# STM32F334R8T7 register map
File version: 1.0
Registers are 32-bit, access not given, reset 0x0 unless marked. A register's access mark holds for its fields unless they carry their own. Offsets are from the block's base; [hi:lo] are bit positions; {n}, {i} and the like mark numbered series.

## HRTIM1_COMMON
Base 0x40017780
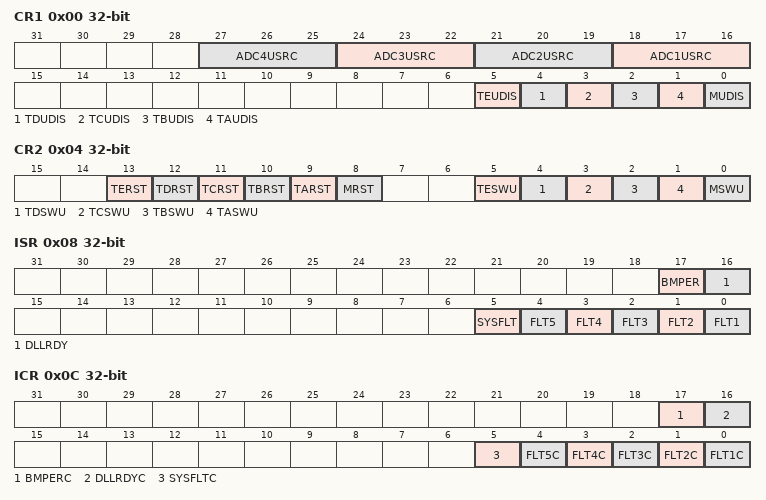
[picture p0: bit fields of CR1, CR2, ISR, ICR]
0x00 CR1
  [3n+15:3n+13] ADC{n}USRC (n=1..4), [5] TEUDIS, [4] TDUDIS, [3] TCUDIS, [2] TBUDIS, [1] TAUDIS, [0] MUDIS
0x04 CR2
  [13] TERST, [12] TDRST, [11] TCRST, [10] TBRST, [9] TARST, [8] MRST, [5] TESWU, [4] TDSWU, [3] TCSWU, [2] TBSWU, [1] TASWU, [0] MSWU
0x08 ISR
  [17] BMPER, [16] DLLRDY, [5] SYSFLT, [n-1] FLT{n} (n=1..5)
0x0C ICR
  [17] BMPERC, [16] DLLRDYC, [5] SYSFLTC, [n-1] FLT{n}C (n=1..5)
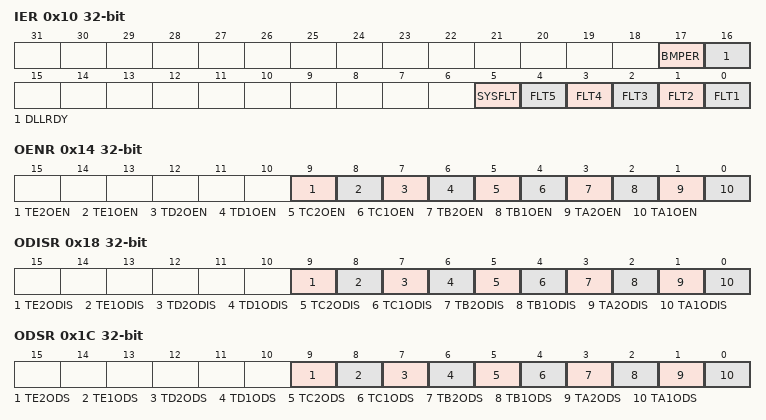
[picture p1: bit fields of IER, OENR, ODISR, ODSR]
0x10 IER
  [17] BMPER, [16] DLLRDY, [5] SYSFLT, [n-1] FLT{n} (n=1..5)
0x14 OENR
  [9] TE2OEN, [8] TE1OEN, [7] TD2OEN, [6] TD1OEN, [5] TC2OEN, [4] TC1OEN, [3] TB2OEN, [2] TB1OEN, [1] TA2OEN, [0] TA1OEN
0x18 ODISR
  [9] TE2ODIS, [8] TE1ODIS, [7] TD2ODIS, [6] TD1ODIS, [5] TC2ODIS, [4] TC1ODIS, [3] TB2ODIS, [2] TB1ODIS, [1] TA2ODIS, [0] TA1ODIS
0x1C ODSR
  [9] TE2ODS, [8] TE1ODS, [7] TD2ODS, [6] TD1ODS, [5] TC2ODS, [4] TC1ODS, [3] TB2ODS, [2] TB1ODS, [1] TA2ODS, [0] TA1ODS
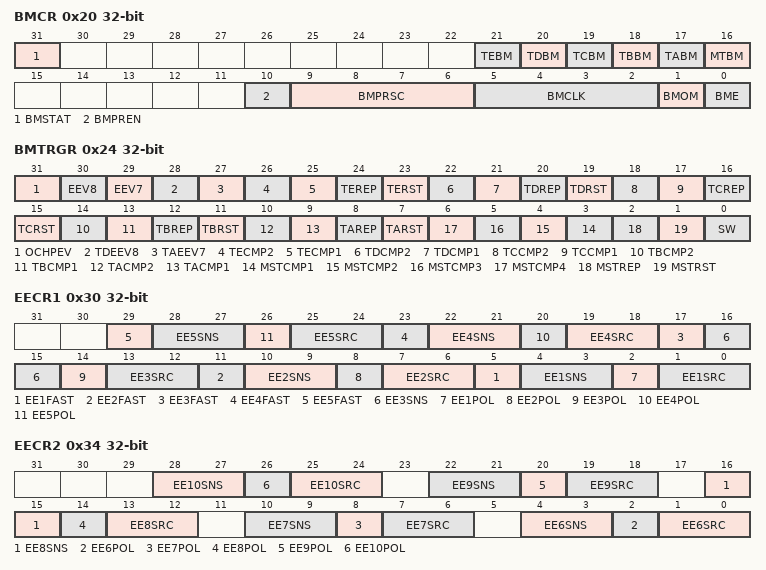
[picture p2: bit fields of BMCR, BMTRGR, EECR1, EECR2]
0x20 BMCR
  [31] BMSTAT, [21] TEBM, [20] TDBM, [19] TCBM, [18] TBBM, [17] TABM, [16] MTBM, [10] BMPREN, [9:6] BMPRSC, [5:2] BMCLK, [1] BMOM, [0] BME
0x24 BMTRGR
  [31] OCHPEV, [30] EEV8, [29] EEV7, [28] TDEEV8, [27] TAEEV7, [26] TECMP2, [25] TECMP1, [24] TEREP, [23] TERST, [22] TDCMP2, [21] TDCMP1, [20] TDREP, [19] TDRST, [18] TCCMP2, [17] TCCMP1, [16] TCREP, [15] TCRST, [14] TBCMP2, [13] TBCMP1, [12] TBREP, [11] TBRST, [10] TACMP2, [9] TACMP1, [8] TAREP, [7] TARST, [n+2] MSTCMP{n} (n=1..4), [2] MSTREP, [1] MSTRST, [0] SW
0x28 BMCMPR
  [15:0] BMCMPR
0x2C BMPER
  [15:0] BMPER
0x30 EECR1
  [6n-1] EE{n}FAST (n=1..5), [6n-2:6n-3] EE{n}SNS (n=1..5), [6n-4] EE{n}POL (n=1..5), [6n-5:6n-6] EE{n}SRC (n=1..5)
0x34 EECR2
  [6n-32:6n-33] EE{n}SNS (n=6..10), [6n-34] EE{n}POL (n=6..10), [6n-35:6n-36] EE{n}SRC (n=6..10)
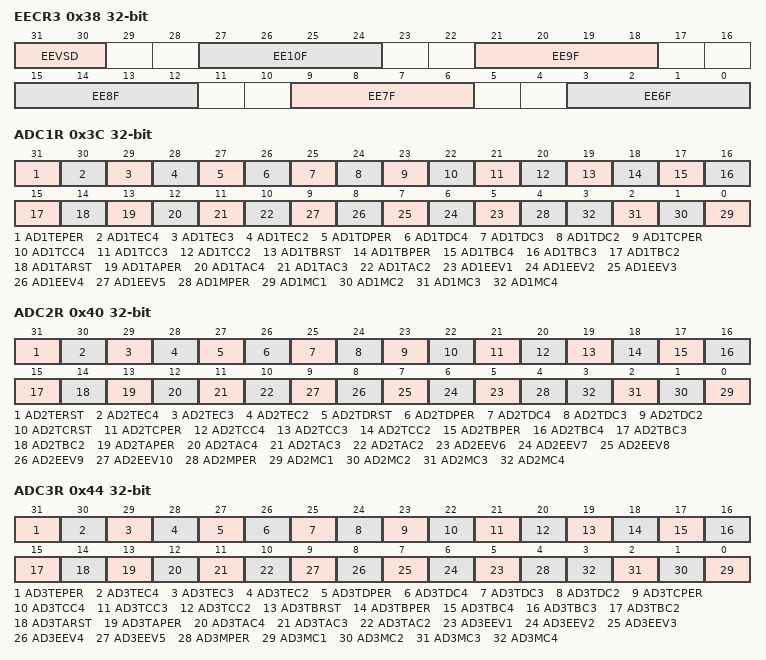
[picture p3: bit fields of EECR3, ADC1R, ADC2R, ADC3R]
0x38 EECR3
  [31:30] EEVSD, [6n-33:6n-36] EE{n}F (n=6..10)
0x3C ADC1R
  [31] AD1TEPER, [30] AD1TEC4, [29] AD1TEC3, [28] AD1TEC2, [27] AD1TDPER, [26] AD1TDC4, [25] AD1TDC3, [24] AD1TDC2, [23] AD1TCPER, [22] AD1TCC4, [21] AD1TCC3, [20] AD1TCC2, [19] AD1TBRST, [18] AD1TBPER, [17] AD1TBC4, [16] AD1TBC3, [15] AD1TBC2, [14] AD1TARST, [13] AD1TAPER, [12] AD1TAC4, [11] AD1TAC3, [10] AD1TAC2, [n+4] AD1EEV{n} (n=1..5), [4] AD1MPER, [n-1] AD1MC{n} (n=1..4)
0x40 ADC2R
  [31] AD2TERST, [30] AD2TEC4, [29] AD2TEC3, [28] AD2TEC2, [27] AD2TDRST, [26] AD2TDPER, [25] AD2TDC4, [24] AD2TDC3, [23] AD2TDC2, [22] AD2TCRST, [21] AD2TCPER, [20] AD2TCC4, [19] AD2TCC3, [18] AD2TCC2, [17] AD2TBPER, [16] AD2TBC4, [15] AD2TBC3, [14] AD2TBC2, [13] AD2TAPER, [12] AD2TAC4, [11] AD2TAC3, [10] AD2TAC2, [n-1] AD2EEV{n} (n=6..10), [4] AD2MPER, [n-1] AD2MC{n} (n=1..4)
0x44 ADC3R
  [31] AD3TEPER, [30] AD3TEC4, [29] AD3TEC3, [28] AD3TEC2, [27] AD3TDPER, [26] AD3TDC4, [25] AD3TDC3, [24] AD3TDC2, [23] AD3TCPER, [22] AD3TCC4, [21] AD3TCC3, [20] AD3TCC2, [19] AD3TBRST, [18] AD3TBPER, [17] AD3TBC4, [16] AD3TBC3, [15] AD3TBC2, [14] AD3TARST, [13] AD3TAPER, [12] AD3TAC4, [11] AD3TAC3, [10] AD3TAC2, [n+4] AD3EEV{n} (n=1..5), [4] AD3MPER, [n-1] AD3MC{n} (n=1..4)
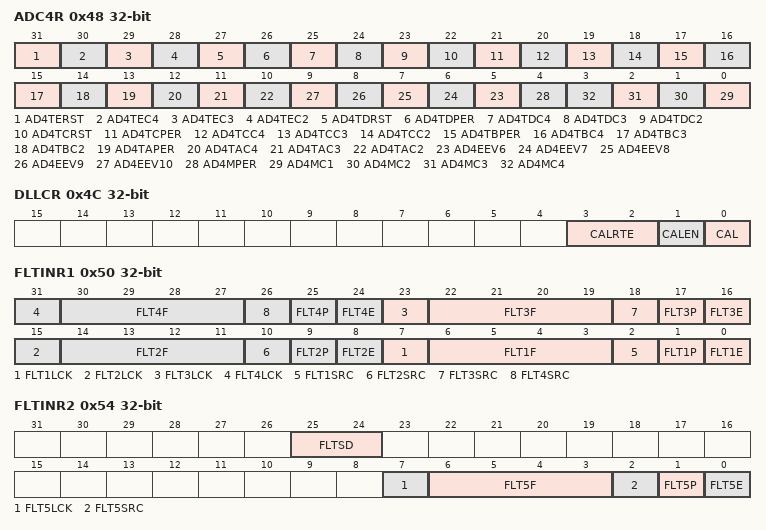
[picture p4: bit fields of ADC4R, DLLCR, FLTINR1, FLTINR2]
0x48 ADC4R
  [31] AD4TERST, [30] AD4TEC4, [29] AD4TEC3, [28] AD4TEC2, [27] AD4TDRST, [26] AD4TDPER, [25] AD4TDC4, [24] AD4TDC3, [23] AD4TDC2, [22] AD4TCRST, [21] AD4TCPER, [20] AD4TCC4, [19] AD4TCC3, [18] AD4TCC2, [17] AD4TBPER, [16] AD4TBC4, [15] AD4TBC3, [14] AD4TBC2, [13] AD4TAPER, [12] AD4TAC4, [11] AD4TAC3, [10] AD4TAC2, [n-1] AD4EEV{n} (n=6..10), [4] AD4MPER, [n-1] AD4MC{n} (n=1..4)
0x4C DLLCR
  [3:2] CALRTE, [1] CALEN, [0] CAL
0x50 FLTINR1
  [8n-1] FLT{n}LCK (n=1..4), [8n-2:8n-5] FLT{n}F (n=1..4), [8n-6] FLT{n}SRC (n=1..4), [8n-7] FLT{n}P (n=1..4), [8n-8] FLT{n}E (n=1..4)
0x54 FLTINR2
  [25:24] FLTSD, [7] FLT5LCK, [6:3] FLT5F, [2] FLT5SRC, [1] FLT5P, [0] FLT5E
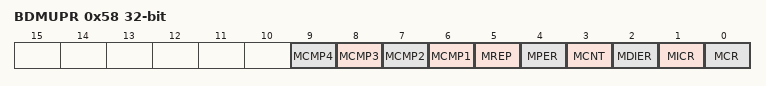
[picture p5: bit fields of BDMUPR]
0x58 BDMUPR
  [n+5] MCMP{n} (n=1..4), [5] MREP, [4] MPER, [3] MCNT, [2] MDIER, [1] MICR, [0] MCR
0x5C BDTAUPR
0x60 BDTBUPR
0x64 BDTCUPR
0x68 BDTDUPR
0x6C BDTEUPR
0x70 BDMADR
